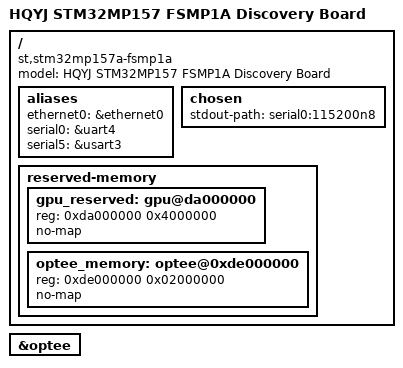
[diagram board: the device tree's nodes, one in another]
// SPDX-License-Identifier: (GPL-2.0+ OR BSD-3-Clause)
/*
 * Copyright (C) STMicroelectronics 2019 - All Rights Reserved
 * Author: Alexandre Torgue <alexandre.torgue@st.com> for STMicroelectronics.
 */

/dts-v1/;

#include "stm32mp157.dtsi"
#include "stm32mp15xa.dtsi"
#include "stm32mp15-pinctrl.dtsi"
#include "stm32mp15xxaa-pinctrl.dtsi"
#include "stm32mp15xx-fsmp1x.dtsi"
/ {
	model = "HQYJ STM32MP157 FSMP1A Discovery Board";
	compatible = "st,stm32mp157a-fsmp1a", "st,stm32mp157";

	aliases {
		ethernet0 = &ethernet0;
		serial0 = &uart4;
		serial5 = &usart3;
	};

	chosen {
		stdout-path = "serial0:115200n8";
	};

	reserved-memory {
		gpu_reserved: gpu@da000000 {
			reg = <0xda000000 0x4000000>;
			no-map;
		};

		optee_memory: optee@0xde000000 {
			reg = <0xde000000 0x02000000>;
			no-map;
		};
	};
};

&optee {
	status = "okay";
};
